VERSION ""

NS_ :

BS_:

BU_: Dashboard GPS CAN_Repeater [cite: 6]

BO_ 848 DashStatus: 8 Vector__XXX [cite: 6]

BO_ 768 DashButtons: 8 Dashboard [cite: 6]
 SG_ StartButton : 0|1@1+ (1,0) [0|1] "Bool" Vector__XXX [cite: 6]
 SG_ ModeSwitch : 1|2@1+ (1,0) [0|3] "Enum" Vector__XXX [cite: 6]

BO_ 1024 GPS_Data: 8 GPS [cite: 6]
 SG_ Latitude : 0|32@1- (1E-07,0) [-90|90] "deg" Vector__XXX [cite: 6]
 SG_ Longitude : 32|32@1- (1E-07,0) [-180|180] "deg" Vector__XXX [cite: 6]

BO_ 2016 RepeaterStatus: 8 CAN_Repeater
 SG_ QueueDepth_1to2 : 0|8@1+ (1,0) [0|255] "msgs" Vector__XXX
 SG_ QueueDepth_2to1 : 8|8@1+ (1,0) [0|255] "msgs" Vector__XXX
 SG_ CAN1_ErrorReg : 16|8@1+ (1,0) [0|255] "hex" Vector__XXX
 SG_ CAN2_ErrorReg : 24|8@1+ (1,0) [0|255] "hex" Vector__XXX
 SG_ Uptime : 32|32@0+ (1,0) [0|4294967295] "s" Vector__XXX

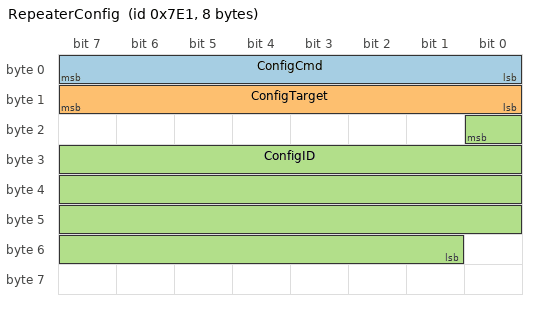
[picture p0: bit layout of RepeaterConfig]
BO_ 2017 RepeaterConfig: 8 Vector__XXX
 SG_ ConfigCmd : 0|8@1+ (1,0) [0|255] "" Vector__XXX
 SG_ ConfigTarget : 8|8@1+ (1,0) [0|255] "" Vector__XXX
 SG_ ConfigID : 16|32@0+ (1,0) [0|4294967295] "" Vector__XXX

CM_ BU_ Dashboard "Driver inputs and display"; [cite: 7]
CM_ BU_ GPS "Vehicle telemetry positioning"; [cite: 7]
CM_ BU_ CAN_Repeater "Dual-channel CAN gateway and filter";

BA_DEF_ BO_  "GenMsgCycleTime" INT 0 100000; [cite: 8]
BA_DEF_  "BusType" STRING ; [cite: 8]
BA_DEF_DEF_  "GenMsgCycleTime" 0; [cite: 8]
BA_DEF_DEF_  "BusType" "CAN"; [cite: 8]

BA_ "GenMsgCycleTime" BO_ 768 50; [cite: 9]
BA_ "GenMsgCycleTime" BO_ 1024 100; [cite: 9]
BA_ "GenMsgCycleTime" BO_ 2016 100;

VAL_ 768 ModeSwitch 0 "Eco" 1 "Sport" 2 "Race" ; [cite: 9]
VAL_ 2017 ConfigCmd 0 "ClearList" 1 "AddID" 2 "RemoveID" ;
VAL_ 2017 ConfigTarget 0 "CAN1_to_2" 1 "CAN2_to_1" ;
